AUTOSAR XML (schema 4-2-2)
standard types defined: uint16
package /PortInterfaces
  sender receiver interface BrakePosition_I
    data BrakePosition: type=uint16
package /ComponentTypes
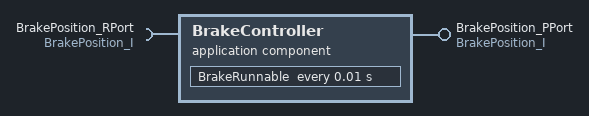
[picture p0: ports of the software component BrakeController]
  application sw component type BrakeController
    provide port BrakePosition_PPort: nonqueued-sender-com-spec=data-element=BrakePosition, provided-interface=BrakePosition_I
    require port BrakePosition_RPort: nonqueued-receiver-com-spec{data-element=BrakePosition, filter=data-filter-type=ALWAYS}, required-interface=BrakePosition_I
    behavior BrakeController_InternalBehavior
      timing event TMT_BrakeRunnable: start-on-event=BrakeRunnable, period=0.01
      port-api-options:
        enable-take-address=false, indirect-api=false, port=BrakePosition_PPort
        enable-take-address=false, indirect-api=false, port=BrakePosition_RPort
      runnable BrakeRunnable
  swc implementation BrakeController_Implementation: behavior=BrakeController_InternalBehavior
